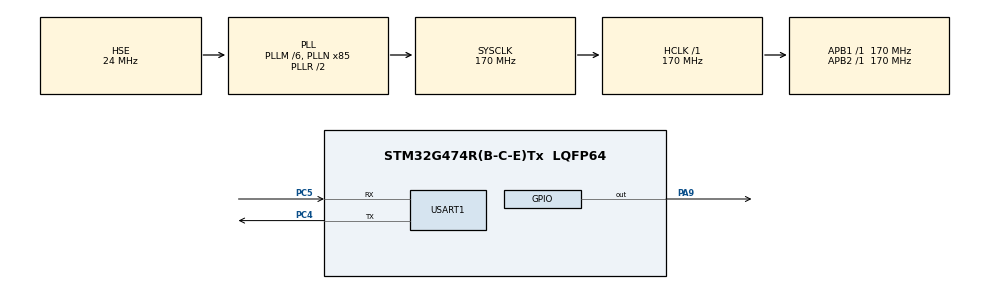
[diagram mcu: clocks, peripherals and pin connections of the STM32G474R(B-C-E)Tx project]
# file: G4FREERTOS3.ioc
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FREERTOS.Tasks01=defaultTask,0,128,StartDefaultTask,Default,NULL,Dynamic,NULL,NULL;myTask02,-3,128,StartTask02,Default,NULL,Dynamic,NULL,NULL
Mcu.Family=STM32G4
Mcu.Name=STM32G474R(B-C-E)Tx
Mcu.Package=LQFP64
NVIC.PriorityGroup=NVIC_PRIORITYGROUP_4
NVIC.TIM1_UP_TIM16_IRQn=true\:15\:0\:false\:false\:true\:false\:false\:true\:true
NVIC.TimeBase=TIM1_UP_TIM16_IRQn
NVIC.TimeBaseIP=TIM1
PA13.Mode=Serial_Wire
PA13.Signal=SYS_JTMS-SWDIO
PA14.Mode=Serial_Wire
PA14.Signal=SYS_JTCK-SWCLK
PA9.Signal=GPIO_Output
PC4.Mode=Asynchronous
PC4.Signal=USART1_TX
PC5.Mode=Asynchronous
PC5.Signal=USART1_RX
PF0-OSC_IN.Mode=HSE-External-Oscillator
PF0-OSC_IN.Signal=RCC_OSC_IN
PF1-OSC_OUT.Mode=HSE-External-Oscillator
PF1-OSC_OUT.Signal=RCC_OSC_OUT
ProjectManager.HeapSize=0x200
ProjectManager.StackSize=0x400
ProjectManager.TargetToolchain=STM32CubeIDE
RCC.ADC12Freq_Value=170000000
RCC.ADC345Freq_Value=170000000
RCC.AHBFreq_Value=170000000
RCC.APB1Freq_Value=170000000
RCC.APB1TimFreq_Value=170000000
RCC.APB2Freq_Value=170000000
RCC.APB2TimFreq_Value=170000000
RCC.CortexFreq_Value=170000000
RCC.EXTERNAL_CLOCK_VALUE=12288000
RCC.HCLKFreq_Value=170000000
RCC.HSE_VALUE=24000000
RCC.HSI48_VALUE=48000000
RCC.HSI_VALUE=16000000
RCC.PLLM=RCC_PLLM_DIV6
RCC.PLLN=85
RCC.PLLSourceVirtual=RCC_PLLSOURCE_HSE
RCC.SYSCLKFreq_VALUE=170000000
RCC.SYSCLKSource=RCC_SYSCLKSOURCE_PLLCLK
RCC.USBFreq_Value=170000000
RCC.VCOOutputFreq_Value=340000000
USART1.VirtualMode-Asynchronous=VM_ASYNC
VP_FREERTOS_VS_CMSIS_V1.Mode=CMSIS_V1
VP_SYS_VS_DBSignals.Mode=DisableDeadBatterySignals
VP_SYS_VS_tim1.Mode=TIM1
board=custom

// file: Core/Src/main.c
/* USER CODE BEGIN Header */
/**
  ******************************************************************************
  * @file           : main.c
  * @brief          : Main program body
  ******************************************************************************
  * @attention
  *
  * Copyright (c) 2023 STMicroelectronics.
  * All rights reserved.
  *
  * This software is licensed under terms that can be found in the LICENSE file
  * in the root directory of this software component.
  * If no LICENSE file comes with this software, it is provided AS-IS.
  *
  ******************************************************************************
  */
/* USER CODE END Header */
#include "main.h"
#include "cmsis_os.h"
#include "usart.h"
#include "gpio.h"
#include <stdio.h>

/* USER CODE BEGIN PTD */
#ifdef __GNUC__
/* With GCC/RAISONANCE, small printf (option LD Linker->Libraries->Small printf set to 'Yes') calls __io_putchar() */
#define PUTCHAR_PROTOTYPE int __io_putchar(int ch)
#else
#define PUTCHAR_PROTOTYPE int fputc(int ch, FILE *f)
#endif /* __GNUC__ */
PUTCHAR_PROTOTYPE
{
    /* Place your implementation of fputc here */
    /* e.g. write a character to the USART */
    //USART_SendData(USART1, (uint8_t) ch);
    HAL_UART_Transmit(&huart1, (uint8_t *)&ch, 1, 0xffff);
    /* Loop until the end of transmission */
    //while (USART_GetFlagStatus(USART1, USART_FLAG_TC) == RESET);
    return ch;
}

/* USER CODE END PTD */

void SystemClock_Config(void);
void MX_FREERTOS_Init(void);

int main(void)
{

  /* MCU Configuration--------------------------------------------------------*/

  /* Reset of all peripherals, Initializes the Flash interface and the Systick. */
  HAL_Init();

  /* Configure the system clock */
  SystemClock_Config();

  /* Initialize all configured peripherals */
  MX_GPIO_Init();
  MX_USART1_UART_Init();

  /* Call init function for freertos objects (in freertos.c) */
  MX_FREERTOS_Init();

  /* Start scheduler */
  osKernelStart();

  /* We should never get here as control is now taken by the scheduler */
  /* Infinite loop */
  while (1)
  {

  }
}

void SystemClock_Config(void)
{
  RCC_OscInitTypeDef RCC_OscInitStruct = {0};
  RCC_ClkInitTypeDef RCC_ClkInitStruct = {0};

  /** Configure the main internal regulator output voltage
  */
  HAL_PWREx_ControlVoltageScaling(PWR_REGULATOR_VOLTAGE_SCALE1_BOOST);

  /** Initializes the RCC Oscillators according to the specified parameters
  * in the RCC_OscInitTypeDef structure.
  */
  RCC_OscInitStruct.OscillatorType = RCC_OSCILLATORTYPE_HSE;
  RCC_OscInitStruct.HSEState = RCC_HSE_ON;
  RCC_OscInitStruct.PLL.PLLState = RCC_PLL_ON;
  RCC_OscInitStruct.PLL.PLLSource = RCC_PLLSOURCE_HSE;
  RCC_OscInitStruct.PLL.PLLM = RCC_PLLM_DIV6;
  RCC_OscInitStruct.PLL.PLLN = 85;
  RCC_OscInitStruct.PLL.PLLP = RCC_PLLP_DIV2;
  RCC_OscInitStruct.PLL.PLLQ = RCC_PLLQ_DIV2;
  RCC_OscInitStruct.PLL.PLLR = RCC_PLLR_DIV2;
  if (HAL_RCC_OscConfig(&RCC_OscInitStruct) != HAL_OK)
  {
    Error_Handler();
  }

  /** Initializes the CPU, AHB and APB buses clocks
  */
  RCC_ClkInitStruct.ClockType = RCC_CLOCKTYPE_HCLK|RCC_CLOCKTYPE_SYSCLK
                              |RCC_CLOCKTYPE_PCLK1|RCC_CLOCKTYPE_PCLK2;
  RCC_ClkInitStruct.SYSCLKSource = RCC_SYSCLKSOURCE_PLLCLK;
  RCC_ClkInitStruct.AHBCLKDivider = RCC_SYSCLK_DIV1;
  RCC_ClkInitStruct.APB1CLKDivider = RCC_HCLK_DIV1;
  RCC_ClkInitStruct.APB2CLKDivider = RCC_HCLK_DIV1;

  if (HAL_RCC_ClockConfig(&RCC_ClkInitStruct, FLASH_LATENCY_4) != HAL_OK)
  {
    Error_Handler();
  }
}

void HAL_TIM_PeriodElapsedCallback(TIM_HandleTypeDef *htim)
{
  if (htim->Instance == TIM1) {
    HAL_IncTick();
  }
}

void Error_Handler(void)
{
  __disable_irq();
  while (1)
  {
  }
}

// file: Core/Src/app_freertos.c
/* USER CODE BEGIN Header */
/**
  ******************************************************************************
  * File Name          : app_freertos.c
  * Description        : Code for freertos applications
  ******************************************************************************
  * @attention
  *
  * Copyright (c) 2023 STMicroelectronics.
  * All rights reserved.
  *
  * This software is licensed under terms that can be found in the LICENSE file
  * in the root directory of this software component.
  * If no LICENSE file comes with this software, it is provided AS-IS.
  *
  ******************************************************************************
  */
/* USER CODE END Header */

#include "FreeRTOS.h"
#include "task.h"
#include "main.h"
#include "cmsis_os.h"
#include "stm32g4xx_hal_uart.h"
/* USER CODE BEGIN Includes */
#include <stdio.h>
#define RX_SIZE    200
extern UART_HandleTypeDef huart1;
uint8_t buff[256];
/* USER CODE END Includes */

osThreadId defaultTaskHandle;
osThreadId myTask02Handle;

void StartDefaultTask(void const * argument);
void StartTask02(void const * argument);

void MX_FREERTOS_Init(void); /* (MISRA C 2004 rule 8.1) */

void MX_FREERTOS_Init(void) {

  /* Create the thread(s) */
  /* definition and creation of defaultTask */
  osThreadDef(defaultTask, StartDefaultTask, osPriorityNormal, 0, 128);
  defaultTaskHandle = osThreadCreate(osThread(defaultTask), NULL);

  /* definition and creation of myTask02 */
  osThreadDef(myTask02, StartTask02, osPriorityIdle, 0, 128);
  myTask02Handle = osThreadCreate(osThread(myTask02), NULL);

}

void StartDefaultTask(void const * argument)
{
  /* USER CODE BEGIN StartDefaultTask */
  /* Infinite loop */
  for(;;)
  {
      HAL_GPIO_TogglePin(GPIOA,GPIO_PIN_9);
    osDelay(1000);
  }
  /* USER CODE END StartDefaultTask */
}

void StartTask02(void const * argument) {
    /* USER CODE BEGIN StartTask02 */
    /* Infinite loop */
    for (;;) {

                int a;
                //HAL_UART_Transmit(&huart1,(unsigned char *)"hello", 5, 50);

                printf("Hello \r\n");
            osDelay(1000);
        }
        /* USER CODE END StartTask02 */
    }
